# TESTMCU register map
Registers are access not given, no defined reset value unless marked. A register's access mark holds for its fields unless they carry their own. Offsets are from the block's base; lines under a group give offsets from that group; [hi:lo] are bit positions; {n}, {i} and the like mark numbered series; 'fields as' and 'values as' point back to an identical list; <NAME> marks a mode.

## Memory map
0x40000000 TIM2 — General purpose timer
0x40004400 USART2
0x40008000 LPUART1
0x40011000 USART1 — Universal synchronous asynchronous receiver transmitter
0x40020000 GPIOA
0x40023800 RCC — Reset and clock control

## Interrupts
28 TIM2
37 USART1 — USART1 global interrupt
38 USART2

## RCC — Reset and clock control
Base 0x40023800
0x24 APB2RSTR
  [4] USART1RST
0x30 AHB1ENR — AHB1 peripheral clock enable register
  [0] GPIOAEN — IO port A clock enable
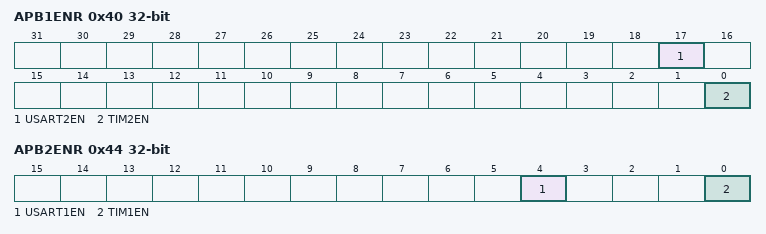
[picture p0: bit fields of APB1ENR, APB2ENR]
0x40 APB1ENR
  [17] USART2EN, [0] TIM2EN
0x44 APB2ENR — APB2 peripheral clock enable register
  [4] USART1EN — USART1 clock enable
  [0] TIM1EN
0x64 APB2LPENR
  [4] USART1LPEN

## USART1 — Universal synchronous asynchronous receiver transmitter
Base 0x40011000
Same registers: USART2 0x40004400
0x00 CR1 — Control register 1
  [0] UE — USART enable
0x04 CR2
0x1C ISR — Interrupt and status register

## LPUART1
Base 0x40008000
0x00 CR1

## TIM2 — General purpose timer
Base 0x40000000
0x00 CR1
0x18 CCMR group
  0x00 OUT

## GPIOA
Base 0x40020000
0x00 MODER
